VERSION ""

NS_ :

BS_:

BU_: XXX 0

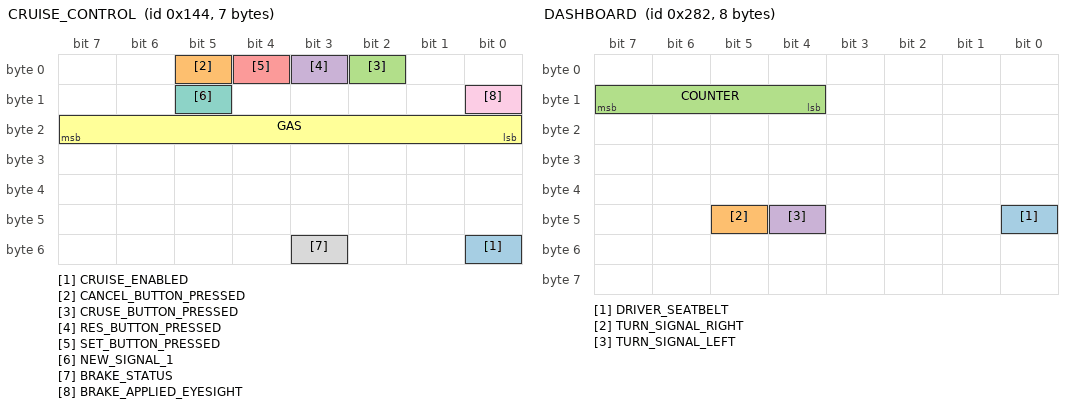
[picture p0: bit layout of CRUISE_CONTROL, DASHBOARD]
BO_ 324 CRUISE_CONTROL: 7 XXX
 SG_ CRUISE_ENABLED : 48|1@0+ (1,0) [0|0] "" XXX
 SG_ CANCEL_BUTTON_PRESSED : 5|1@0+ (1,0) [0|1] "" XXX
 SG_ CRUSE_BUTTON_PRESSED : 2|1@0+ (1,0) [0|1] "" XXX
 SG_ RES_BUTTON_PRESSED : 3|1@0+ (1,0) [0|1] "" XXX
 SG_ SET_BUTTON_PRESSED : 4|1@0+ (1,0) [0|1] "" XXX
 SG_ GAS : 16|8@1+ (1,0) [0|255] "" XXX
 SG_ NEW_SIGNAL_1 : 13|1@0+ (1,0) [0|1] "" XXX
 SG_ BRAKE_STATUS : 51|1@0+ (1,0) [0|0] "" XXX
 SG_ BRAKE_APPLIED_EYESIGHT : 8|1@0+ (1,0) [0|1] "" XXX

BO_ 642 DASHBOARD: 8 XXX
 SG_ DRIVER_SEATBELT : 40|1@0+ (1,0) [0|1] "" XXX
 SG_ TURN_SIGNAL_RIGHT : 45|1@0+ (1,0) [0|1] "" XXX
 SG_ COUNTER : 12|4@1+ (1,0) [0|255] "" XXX
 SG_ TURN_SIGNAL_LEFT : 44|1@0+ (1,0) [0|1] "" XXX

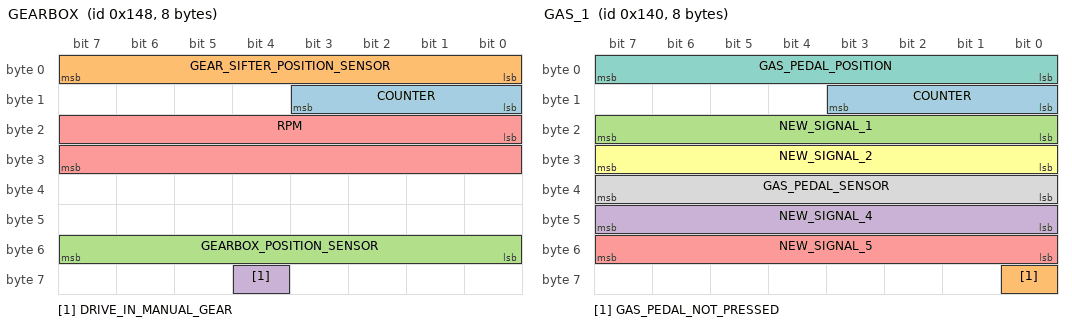
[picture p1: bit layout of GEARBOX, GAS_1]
BO_ 328 GEARBOX: 8 XXX
 SG_ COUNTER : 8|4@1+ (1,0) [0|255] "" XXX
 SG_ GEAR_SIFTER_POSITION_SENSOR : 0|8@1+ (1,0) [0|255] "" XXX
 SG_ GEARBOX_POSITION_SENSOR : 48|8@1+ (1,0) [0|255] "" XXX
 SG_ DRIVE_IN_MANUAL_GEAR : 60|1@0+ (1,0) [0|1] "" XXX
 SG_ RPM : 16|16@1+ (1,0) [0|65535] "" XXX

BO_ 320 GAS_1: 8 XXX
 SG_ COUNTER : 8|4@1+ (1,0) [0|15] "" XXX
 SG_ GAS_PEDAL_NOT_PRESSED : 56|1@0+ (1,0) [0|1] "" XXX
 SG_ NEW_SIGNAL_1 : 23|8@0+ (1,0) [0|255] "" XXX
 SG_ NEW_SIGNAL_4 : 47|8@0+ (1,0) [0|255] "" XXX
 SG_ NEW_SIGNAL_5 : 55|8@0+ (1,0) [0|255] "" XXX
 SG_ NEW_SIGNAL_2 : 31|8@0+ (1,0) [0|255] "" XXX
 SG_ GAS_PEDAL_POSITION : 0|8@1+ (1,0) [0|255] "" XXX
 SG_ GAS_PEDAL_SENSOR : 39|8@0+ (1,0) [0|255] "" XXX

BO_ 209 SPEED_AND_BRAKE_PEDAL: 8 XXX
 SG_ BRAKE_PEDAL_POSITION : 23|8@0+ (1,0) [0|255] "" XXX
 SG_ VEHICLE_SPEED : 0|16@1+ (1,0) [0|65535] "" XXX

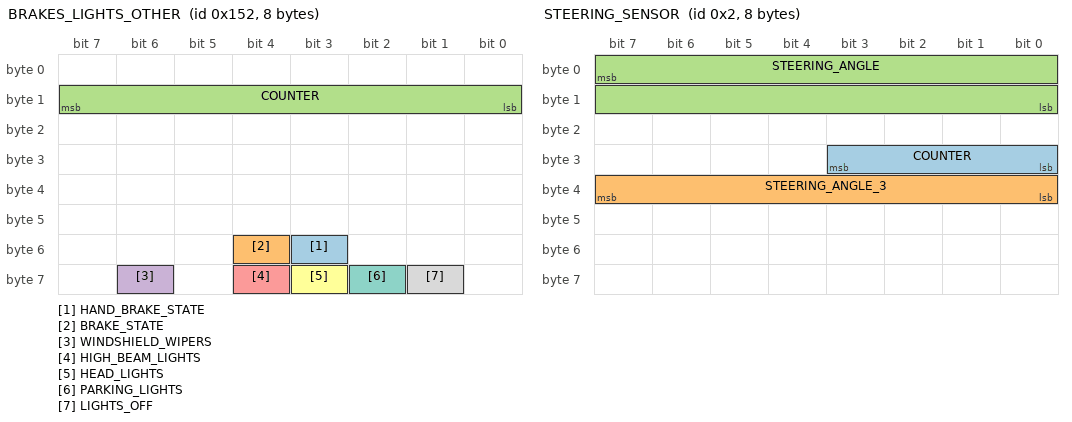
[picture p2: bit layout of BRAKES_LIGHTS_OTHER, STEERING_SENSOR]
BO_ 338 BRAKES_LIGHTS_OTHER: 8 XXX
 SG_ HAND_BRAKE_STATE : 51|1@0+ (1,0) [0|1] "" XXX
 SG_ BRAKE_STATE : 52|1@0+ (1,0) [0|1] "" XXX
 SG_ COUNTER : 8|8@1+ (1,0) [0|255] "" XXX
 SG_ WINDSHIELD_WIPERS : 62|1@0+ (1,0) [0|1] "" XXX
 SG_ HIGH_BEAM_LIGHTS : 60|1@0+ (1,0) [0|1] "" XXX
 SG_ HEAD_LIGHTS : 59|1@0+ (1,0) [0|1] "" XXX
 SG_ PARKING_LIGHTS : 58|1@0+ (1,0) [0|1] "" XXX
 SG_ LIGHTS_OFF : 57|1@0+ (1,0) [0|1] "" XXX

BO_ 2 STEERING_SENSOR: 8 XXX
 SG_ COUNTER : 24|4@1+ (1,0) [0|255] "" XXX
 SG_ STEERING_ANGLE_3 : 39|8@0+ (1,0) [0|255] "" XXX
 SG_ STEERING_ANGLE : 7|16@0- (0.1,0) [-510|510] "degree" XXX

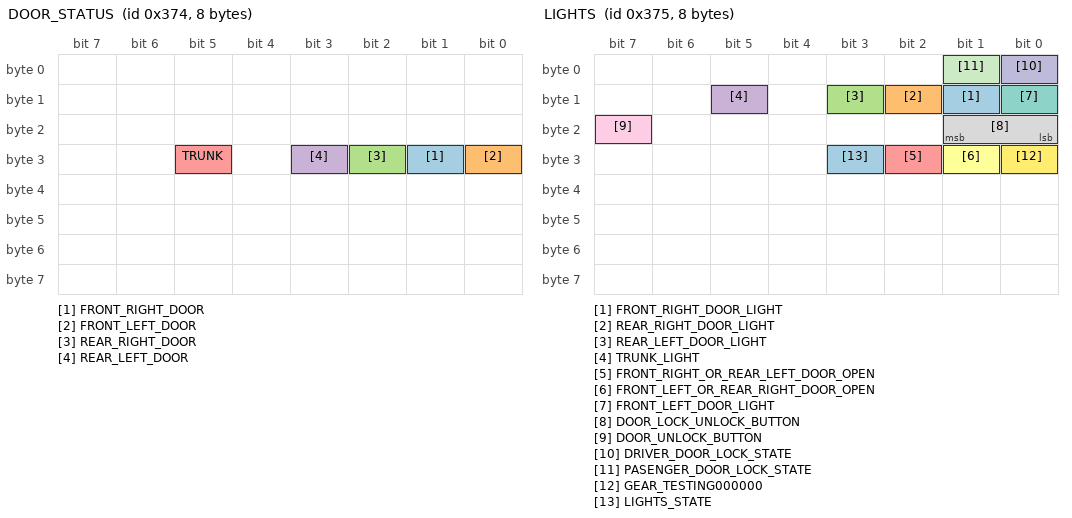
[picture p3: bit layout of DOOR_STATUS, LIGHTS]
BO_ 884 DOOR_STATUS: 8 XXX
 SG_ FRONT_RIGHT_DOOR : 25|1@0+ (1,0) [0|1] "" XXX
 SG_ FRONT_LEFT_DOOR : 24|1@0+ (1,0) [0|1] "" XXX
 SG_ REAR_RIGHT_DOOR : 26|1@0+ (1,0) [0|1] "" XXX
 SG_ REAR_LEFT_DOOR : 27|1@0+ (1,0) [0|1] "" XXX
 SG_ TRUNK : 29|1@0+ (1,0) [0|1] "" XXX

BO_ 885 LIGHTS: 8 XXX
 SG_ FRONT_RIGHT_DOOR_LIGHT : 9|1@0+ (1,0) [0|1] "" XXX
 SG_ REAR_RIGHT_DOOR_LIGHT : 10|1@0+ (1,0) [0|1] "" XXX
 SG_ REAR_LEFT_DOOR_LIGHT : 11|1@0+ (1,0) [0|1] "" XXX
 SG_ TRUNK_LIGHT : 13|1@0+ (1,0) [0|1] "" XXX
 SG_ FRONT_RIGHT_OR_REAR_LEFT_DOOR_OPEN : 26|1@0+ (1,0) [0|1] "" XXX
 SG_ FRONT_LEFT_OR_REAR_RIGHT_DOOR_OPEN : 25|1@0+ (1,0) [0|1] "" XXX
 SG_ FRONT_LEFT_DOOR_LIGHT : 8|1@0+ (1,0) [0|1] "" XXX
 SG_ DOOR_LOCK_UNLOCK_BUTTON : 16|2@1+ (1,0) [0|3] "" XXX
 SG_ DOOR_UNLOCK_BUTTON : 23|1@0+ (1,0) [0|1] "" XXX
 SG_ DRIVER_DOOR_LOCK_STATE : 0|1@0+ (1,0) [0|1] "" XXX
 SG_ PASENGER_DOOR_LOCK_STATE : 1|1@0+ (1,0) [0|1] "" XXX
 SG_ GEAR_TESTING000000 : 24|1@0+ (1,0) [0|1] "" XXX
 SG_ LIGHTS_STATE : 27|1@0+ (1,0) [0|1] "" XXX

BO_ 1632 NEW_MSG_1: 8 XXX
 SG_ COUNTER : 63|8@0+ (1,0) [0|255] "" XXX

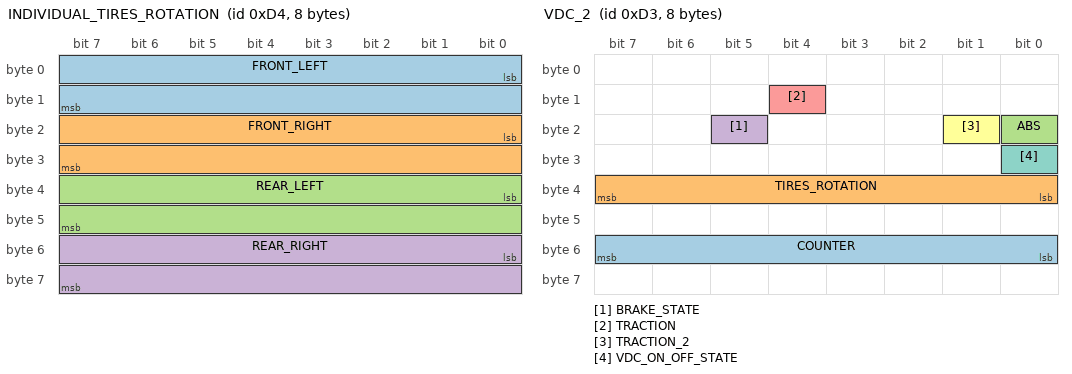
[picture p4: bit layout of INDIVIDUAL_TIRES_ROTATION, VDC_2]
BO_ 212 INDIVIDUAL_TIRES_ROTATION: 8 XXX
 SG_ FRONT_LEFT : 0|16@1+ (1,0) [0|65535] "" XXX
 SG_ FRONT_RIGHT : 16|16@1+ (1,0) [0|65535] "" XXX
 SG_ REAR_LEFT : 32|16@1+ (1,0) [0|65535] "" XXX
 SG_ REAR_RIGHT : 48|16@1+ (1,0) [0|65535] "" XXX

BO_ 342 FUEL_LEVEL: 8 XXX
 SG_ FUEL_LEVEL : 63|8@0+ (1,0) [0|255] "" XXX

BO_ 1786 NEW_MSG_3: 8 XXX
 SG_ COUNTER : 3|4@0+ (1,0) [0|255] "" XXX

BO_ 882 NEW_MSG_4: 8 XXX
 SG_ COUNTER : 15|4@0+ (1,0) [0|15] "" XXX

BO_ 211 VDC_2: 8 XXX
 SG_ COUNTER : 55|8@0+ (1,0) [0|255] "" XXX
 SG_ TIRES_ROTATION : 32|8@1+ (1,0) [0|255] "" XXX
 SG_ ABS : 16|1@0+ (1,0) [0|1] "" XXX
 SG_ BRAKE_STATE : 21|1@0+ (1,0) [0|1] "" XXX
 SG_ TRACTION : 12|1@0+ (1,0) [0|1] "" XXX
 SG_ TRACTION_2 : 17|1@1+ (1,0) [0|15] "" XXX
 SG_ VDC_ON_OFF_STATE : 24|1@0+ (1,0) [0|1] "" XXX

BO_ 329 SPEED_AND_RPM: 8 XXX
 SG_ RPM : 0|8@1+ (1,0) [0|255] "" XXX
 SG_ SPEED_ABOVE_14KM_15KM : 8|4@1+ (1,0) [0|255] "" XXX

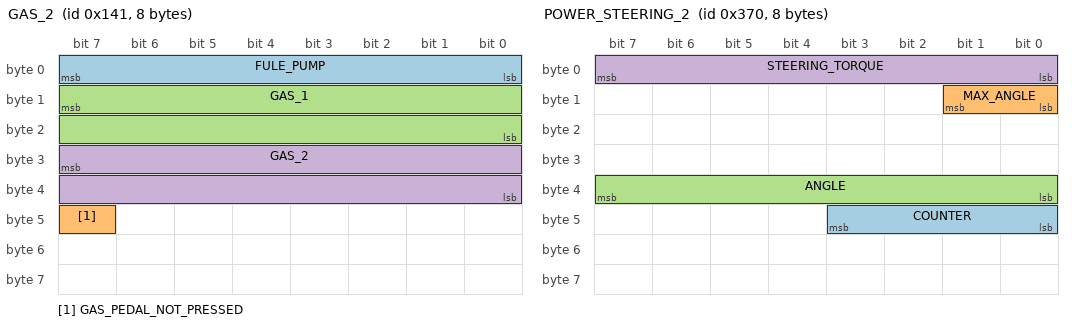
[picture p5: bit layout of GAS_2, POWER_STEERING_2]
BO_ 321 GAS_2: 8 XXX
 SG_ FULE_PUMP : 0|8@1+ (1,0) [0|255] "" XXX
 SG_ GAS_PEDAL_NOT_PRESSED : 47|1@1+ (1,0) [0|255] "" XXX
 SG_ GAS_1 : 15|16@0+ (1,0) [0|65535] "" XXX
 SG_ GAS_2 : 31|16@0+ (1,0) [0|65535] "" XXX

BO_ 640 NEW_MSG_6: 8 XXX
 SG_ COUNTER : 8|4@1+ (1,0) [0|15] "" XXX

BO_ 865 NEW_MSG_8: 8 XXX
 SG_ COUNTER : 32|4@1+ (1,0) [0|15] "" XXX

BO_ 880 POWER_STEERING_2: 8 XXX
 SG_ COUNTER : 40|4@1+ (1,0) [0|255] "" XXX
 SG_ MAX_ANGLE : 8|2@1+ (1,0) [0|3] "" XXX
 SG_ ANGLE : 32|8@1+ (1,0) [0|255] "" XXX
 SG_ STEERING_TORQUE : 0|8@1+ (1,0) [0|7] "" XXX

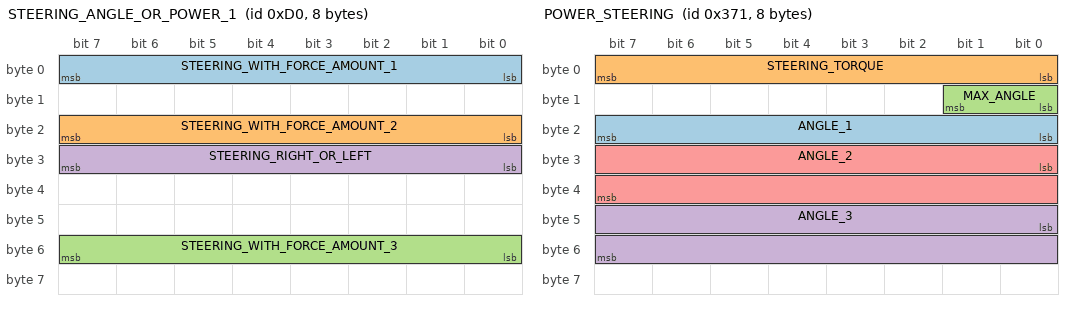
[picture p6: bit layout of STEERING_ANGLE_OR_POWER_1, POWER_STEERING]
BO_ 208 STEERING_ANGLE_OR_POWER_1: 8 XXX
 SG_ STEERING_WITH_FORCE_AMOUNT_1 : 0|8@1+ (1,0) [0|255] "" XXX
 SG_ STEERING_WITH_FORCE_AMOUNT_2 : 16|8@1+ (1,0) [0|255] "" XXX
 SG_ STEERING_WITH_FORCE_AMOUNT_3 : 48|8@1+ (1,0) [0|255] "" XXX
 SG_ STEERING_RIGHT_OR_LEFT : 24|8@1+ (1,0) [0|255] "" XXX

BO_ 881 POWER_STEERING: 8 XXX
 SG_ ANGLE_1 : 16|8@1+ (1,0) [0|255] "" XXX
 SG_ STEERING_TORQUE : 0|8@1+ (1,0) [0|255] "" XXX
 SG_ MAX_ANGLE : 8|2@1+ (1,0) [0|3] "" XXX
 SG_ ANGLE_3 : 40|16@1+ (1,0) [0|65535] "" XXX
 SG_ ANGLE_2 : 24|16@1+ (1,0) [0|65535] "" XXX

BO_ 977 NEW_MSG_5: 8 XXX

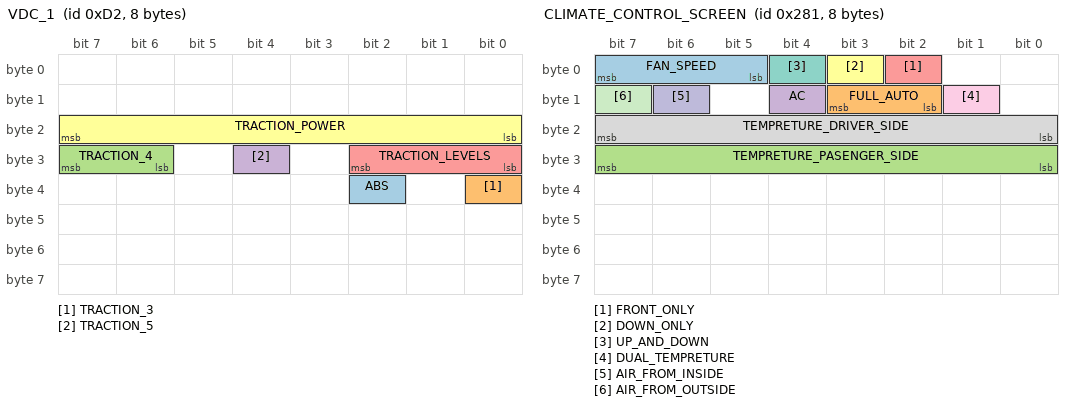
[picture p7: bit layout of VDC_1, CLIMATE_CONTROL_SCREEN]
BO_ 210 VDC_1: 8 XXX
 SG_ ABS : 34|1@0+ (1,0) [0|1] "" XXX
 SG_ TRACTION_3 : 32|1@1+ (1,0) [0|3] "" XXX
 SG_ TRACTION_4 : 31|2@0+ (1,0) [0|15] "" XXX
 SG_ TRACTION_5 : 28|1@0+ (1,0) [0|1] "" XXX
 SG_ TRACTION_LEVELS : 24|3@1+ (1,0) [0|255] "" XXX
 SG_ TRACTION_POWER : 16|8@1+ (1,0) [0|255] "" XXX

BO_ 864 UNKNOWN: 8 XXX
 SG_ ACTIVE_FEW_SECOND_WHEN_IGNETION_ON : 45|1@0+ (1,0) [0|1] "" XXX

BO_ 872 NEW_MSG_7: 8 XXX
 SG_ NEW_SIGNAL_2 : 31|4@0+ (1,0) [0|15] "" XXX

BO_ 644 NEW_MSG_9: 8 XXX

BO_ 641 CLIMATE_CONTROL_SCREEN: 8 XXX
 SG_ FAN_SPEED : 7|3@0+ (1,0) [0|15] "" XXX
 SG_ FULL_AUTO : 10|2@1+ (1,0) [0|3] "" XXX
 SG_ TEMPRETURE_PASENGER_SIDE : 24|8@1+ (1,0) [0|255] "" XXX
 SG_ AC : 12|1@0+ (1,0) [0|1] "" XXX
 SG_ FRONT_ONLY : 2|1@0+ (1,0) [0|1] "" XXX
 SG_ DOWN_ONLY : 3|1@0+ (1,0) [0|1] "" XXX
 SG_ UP_AND_DOWN : 4|1@0+ (1,0) [0|1] "" XXX
 SG_ TEMPRETURE_DRIVER_SIDE : 16|8@1+ (1,0) [0|255] "" XXX
 SG_ DUAL_TEMPRETURE : 9|1@0+ (1,0) [0|1] "" XXX
 SG_ AIR_FROM_INSIDE : 14|1@0+ (1,0) [0|1] "" XXX
 SG_ AIR_FROM_OUTSIDE : 15|1@0+ (1,0) [0|1] "" XXX

BO_ 886 INSIDE_LIGHTS_INTENSITY: 8 XXX
 SG_ INTERIOR_LIGHTS_INTENSITY : 7|8@0+ (1,0) [0|255] "" XXX
